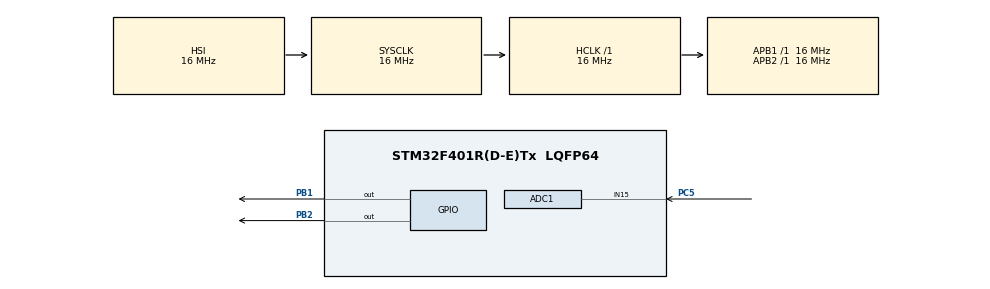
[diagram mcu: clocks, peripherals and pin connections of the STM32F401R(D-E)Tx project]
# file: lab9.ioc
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ADC1.Channel-0\#ChannelRegularConversion=ADC_CHANNEL_15
ADC1.ExternalTrigConv=ADC_EXTERNALTRIGCONV_T2_TRGO
ADC1.NbrOfConversionFlag=1
ADC1.Rank-0\#ChannelRegularConversion=1
ADC1.SamplingTime-0\#ChannelRegularConversion=ADC_SAMPLETIME_3CYCLES
ADC1.master=1
Mcu.Family=STM32F4
Mcu.Name=STM32F401R(D-E)Tx
Mcu.Package=LQFP64
NVIC.ADC_IRQn=true\:0\:0\:false\:false\:true\:true\:true\:true
NVIC.PriorityGroup=NVIC_PRIORITYGROUP_4
NVIC.TIM2_IRQn=true\:0\:0\:false\:false\:true\:true\:true\:true
PB1.GPIO_PuPd=GPIO_PULLDOWN
PB1.Signal=GPIO_Output
PB2.Signal=GPIO_Output
PC5.Signal=ADCx_IN15
ProjectManager.HeapSize=0x200
ProjectManager.StackSize=0x400
ProjectManager.TargetToolchain=MDK-ARM V5.32
RCC.AHBFreq_Value=16000000
RCC.APB1Freq_Value=16000000
RCC.APB2Freq_Value=16000000
RCC.CortexFreq_Value=16000000
RCC.HSE_VALUE=25000000
RCC.HSI_VALUE=16000000
RCC.LSE_VALUE=32768
RCC.SYSCLKFreq_VALUE=16000000
RCC.VCOOutputFreq_Value=192000000
SH.ADCx_IN15.0=ADC1_IN15,IN15
TIM2.Period=999
TIM2.Prescaler=15999
TIM2.TIM_MasterOutputTrigger=TIM_TRGO_UPDATE
TIM2.TIM_MasterSlaveMode=TIM_MASTERSLAVEMODE_ENABLE
VP_TIM2_VS_ClockSourceINT.Mode=Internal
board=custom

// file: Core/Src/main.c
/* USER CODE BEGIN Header */
/**
  ******************************************************************************
  * @file           : main.c
  * @brief          : Main program body
  ******************************************************************************
  * @attention
  *
  * Copyright (c) 2022 STMicroelectronics.
  * All rights reserved.
  *
  * This software is licensed under terms that can be found in the LICENSE file
  * in the root directory of this software component.
  * If no LICENSE file comes with this software, it is provided AS-IS.
  *
  ******************************************************************************
  */
/* USER CODE END Header */
#include "main.h"

 ADC_HandleTypeDef hadc1;

TIM_HandleTypeDef htim2;

void SystemClock_Config(void);
static void MX_GPIO_Init(void);
static void MX_ADC1_Init(void);
static void MX_TIM2_Init(void);
/* USER CODE BEGIN PFP */
uint16_t ADC_Value;
float Voltage;
float temp;
/* USER CODE END PFP */

void HAL_ADC_ConvCpltCallback(ADC_HandleTypeDef* hadc)
{
    // Read & Update The ADC Result
    ADC_Value = HAL_ADC_GetValue(&hadc1);
		Voltage = (float) (ADC_Value*3.3)/4095;
		temp = Voltage*100;
		if (temp<27){
		HAL_GPIO_WritePin(GPIOB,GPIO_PIN_2,1);
		HAL_GPIO_WritePin(GPIOB,GPIO_PIN_1,0);
		}
		else{
		HAL_GPIO_WritePin(GPIOB,GPIO_PIN_2,0);
		HAL_GPIO_WritePin(GPIOB,GPIO_PIN_1,1);
		}
}
int main(void)
{

  /* MCU Configuration--------------------------------------------------------*/

  /* Reset of all peripherals, Initializes the Flash interface and the Systick. */
  HAL_Init();

  /* Configure the system clock */
  SystemClock_Config();

  /* Initialize all configured peripherals */
  MX_GPIO_Init();
  MX_ADC1_Init();
  MX_TIM2_Init();
  /* USER CODE BEGIN 2 */
	HAL_TIM_Base_Start_IT(&htim2);
	HAL_ADC_Start_IT(&hadc1);
  /* USER CODE END 2 */

  /* Infinite loop */
  while (1)
  {

  }
}

void SystemClock_Config(void)
{
  RCC_OscInitTypeDef RCC_OscInitStruct = {0};
  RCC_ClkInitTypeDef RCC_ClkInitStruct = {0};

  /** Configure the main internal regulator output voltage
  */
  __HAL_RCC_PWR_CLK_ENABLE();
  __HAL_PWR_VOLTAGESCALING_CONFIG(PWR_REGULATOR_VOLTAGE_SCALE2);

  /** Initializes the RCC Oscillators according to the specified parameters
  * in the RCC_OscInitTypeDef structure.
  */
  RCC_OscInitStruct.OscillatorType = RCC_OSCILLATORTYPE_HSI;
  RCC_OscInitStruct.HSIState = RCC_HSI_ON;
  RCC_OscInitStruct.HSICalibrationValue = RCC_HSICALIBRATION_DEFAULT;
  RCC_OscInitStruct.PLL.PLLState = RCC_PLL_NONE;
  if (HAL_RCC_OscConfig(&RCC_OscInitStruct) != HAL_OK)
  {
    Error_Handler();
  }

  /** Initializes the CPU, AHB and APB buses clocks
  */
  RCC_ClkInitStruct.ClockType = RCC_CLOCKTYPE_HCLK|RCC_CLOCKTYPE_SYSCLK
                              |RCC_CLOCKTYPE_PCLK1|RCC_CLOCKTYPE_PCLK2;
  RCC_ClkInitStruct.SYSCLKSource = RCC_SYSCLKSOURCE_HSI;
  RCC_ClkInitStruct.AHBCLKDivider = RCC_SYSCLK_DIV1;
  RCC_ClkInitStruct.APB1CLKDivider = RCC_HCLK_DIV1;
  RCC_ClkInitStruct.APB2CLKDivider = RCC_HCLK_DIV1;

  if (HAL_RCC_ClockConfig(&RCC_ClkInitStruct, FLASH_LATENCY_0) != HAL_OK)
  {
    Error_Handler();
  }
}

static void MX_ADC1_Init(void)
{

  ADC_ChannelConfTypeDef sConfig = {0};

  /** Configure the global features of the ADC (Clock, Resolution, Data Alignment and number of conversion)
  */
  hadc1.Instance = ADC1;
  hadc1.Init.ClockPrescaler = ADC_CLOCK_SYNC_PCLK_DIV2;
  hadc1.Init.Resolution = ADC_RESOLUTION_12B;
  hadc1.Init.ScanConvMode = DISABLE;
  hadc1.Init.ContinuousConvMode = DISABLE;
  hadc1.Init.DiscontinuousConvMode = DISABLE;
  hadc1.Init.ExternalTrigConvEdge = ADC_EXTERNALTRIGCONVEDGE_RISING;
  hadc1.Init.ExternalTrigConv = ADC_EXTERNALTRIGCONV_T2_TRGO;
  hadc1.Init.DataAlign = ADC_DATAALIGN_RIGHT;
  hadc1.Init.NbrOfConversion = 1;
  hadc1.Init.DMAContinuousRequests = DISABLE;
  hadc1.Init.EOCSelection = ADC_EOC_SINGLE_CONV;
  if (HAL_ADC_Init(&hadc1) != HAL_OK)
  {
    Error_Handler();
  }

  /** Configure for the selected ADC regular channel its corresponding rank in the sequencer and its sample time.
  */
  sConfig.Channel = ADC_CHANNEL_15;
  sConfig.Rank = 1;
  sConfig.SamplingTime = ADC_SAMPLETIME_3CYCLES;
  if (HAL_ADC_ConfigChannel(&hadc1, &sConfig) != HAL_OK)
  {
    Error_Handler();
  }

}

static void MX_TIM2_Init(void)
{

  TIM_ClockConfigTypeDef sClockSourceConfig = {0};
  TIM_MasterConfigTypeDef sMasterConfig = {0};

  htim2.Instance = TIM2;
  htim2.Init.Prescaler = 15999;
  htim2.Init.CounterMode = TIM_COUNTERMODE_UP;
  htim2.Init.Period = 999;
  htim2.Init.ClockDivision = TIM_CLOCKDIVISION_DIV1;
  htim2.Init.AutoReloadPreload = TIM_AUTORELOAD_PRELOAD_DISABLE;
  if (HAL_TIM_Base_Init(&htim2) != HAL_OK)
  {
    Error_Handler();
  }
  sClockSourceConfig.ClockSource = TIM_CLOCKSOURCE_INTERNAL;
  if (HAL_TIM_ConfigClockSource(&htim2, &sClockSourceConfig) != HAL_OK)
  {
    Error_Handler();
  }
  sMasterConfig.MasterOutputTrigger = TIM_TRGO_UPDATE;
  sMasterConfig.MasterSlaveMode = TIM_MASTERSLAVEMODE_ENABLE;
  if (HAL_TIMEx_MasterConfigSynchronization(&htim2, &sMasterConfig) != HAL_OK)
  {
    Error_Handler();
  }

}

static void MX_GPIO_Init(void)
{
  GPIO_InitTypeDef GPIO_InitStruct = {0};

  /* GPIO Ports Clock Enable */
  __HAL_RCC_GPIOC_CLK_ENABLE();
  __HAL_RCC_GPIOB_CLK_ENABLE();

  /*Configure GPIO pin Output Level */
  HAL_GPIO_WritePin(GPIOB, GPIO_PIN_1|GPIO_PIN_2, GPIO_PIN_RESET);

  /*Configure GPIO pin : PB1 */
  GPIO_InitStruct.Pin = GPIO_PIN_1;
  GPIO_InitStruct.Mode = GPIO_MODE_OUTPUT_PP;
  GPIO_InitStruct.Pull = GPIO_PULLDOWN;
  GPIO_InitStruct.Speed = GPIO_SPEED_FREQ_LOW;
  HAL_GPIO_Init(GPIOB, &GPIO_InitStruct);

  /*Configure GPIO pin : PB2 */
  GPIO_InitStruct.Pin = GPIO_PIN_2;
  GPIO_InitStruct.Mode = GPIO_MODE_OUTPUT_PP;
  GPIO_InitStruct.Pull = GPIO_NOPULL;
  GPIO_InitStruct.Speed = GPIO_SPEED_FREQ_LOW;
  HAL_GPIO_Init(GPIOB, &GPIO_InitStruct);

}

void Error_Handler(void)
{
  __disable_irq();
  while (1)
  {
  }
}
